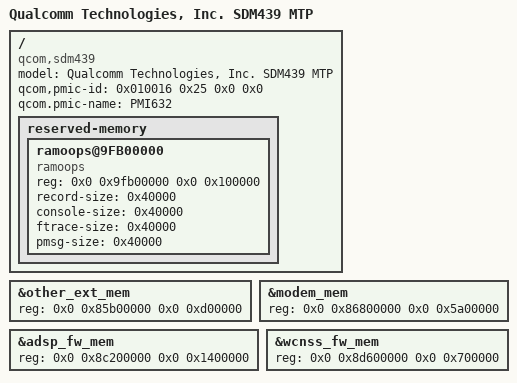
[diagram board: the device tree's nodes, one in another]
/dts-v1/;

#include "sdm439.dtsi"

/ {
	model = "Qualcomm Technologies, Inc. SDM439 MTP";
	compatible = "qcom,sdm439";
	qcom,pmic-id = <0x010016 0x25 0x0 0x0>;
	qcom.pmic-name = "PMI632";
};

/ {
	reserved-memory {
		ramoops@9FB00000 {
			compatible = "ramoops";
			reg = <0x0 0x9fb00000 0x0 0x100000>;
			record-size = <0x40000>;
			console-size = <0x40000>;
			ftrace-size = <0x40000>;
			pmsg-size = <0x40000>;
		};
	};
};

/* a01q: layout de memoria de firmware del A01 */
&other_ext_mem {
	reg = <0x0 0x85b00000 0x0 0xd00000>;
};
&modem_mem {
	reg = <0x0 0x86800000 0x0 0x5a00000>;
};
&adsp_fw_mem {
	reg = <0x0 0x8c200000 0x0 0x1400000>;
};
&wcnss_fw_mem {
	reg = <0x0 0x8d600000 0x0 0x700000>;
};
